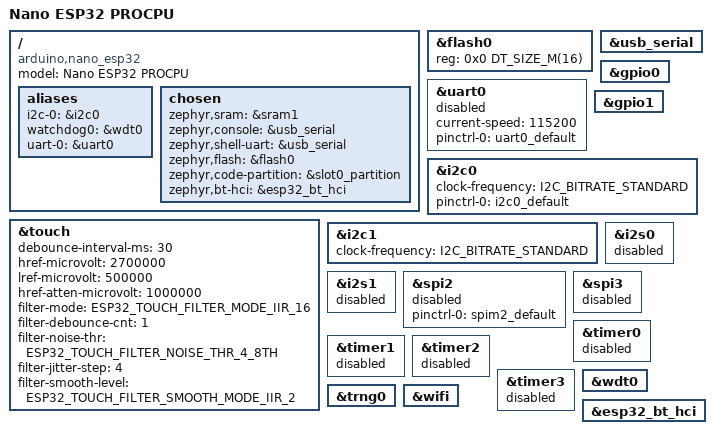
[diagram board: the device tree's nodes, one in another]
/*
 * Copyright (c) 2025 Arduino SA
 *
 * SPDX-License-Identifier: Apache-2.0
 */
/dts-v1/;

#include <espressif/esp32s3/esp32s3_r8.dtsi>
#include <zephyr/dt-bindings/input/input-event-codes.h>
#include <zephyr/dt-bindings/input/esp32-touch-sensor-input.h>
#include "arduino_nano_esp32-partitions.dtsi"
#include "arduino_nano_esp32-pinctrl.dtsi"
#include "arduino_nano_connector.dtsi"

/ {
	model = "Nano ESP32 PROCPU";
	compatible = "arduino,nano_esp32";

	aliases {
		i2c-0 = &i2c0;
		watchdog0 = &wdt0;
	};

	chosen {
		zephyr,sram = &sram1;
		zephyr,console = &usb_serial;
		zephyr,shell-uart = &usb_serial;
		zephyr,flash = &flash0;
		zephyr,code-partition = &slot0_partition;
		zephyr,bt-hci = &esp32_bt_hci;
	};

	aliases {
		uart-0 = &uart0;
	};
};

/* 16MB flash */
&flash0 {
	reg = <0x0 DT_SIZE_M(16)>;
};

&usb_serial {
	status = "okay";
};

&uart0 {
	current-speed = <115200>;
	pinctrl-0 = <&uart0_default>;
	pinctrl-names = "default";
	status = "disabled";
};

&gpio0 {
	status = "okay";
};

&gpio1 {
	status = "okay";
};

&touch {
	debounce-interval-ms = <30>;
	href-microvolt = <2700000>;
	lref-microvolt = <500000>;
	href-atten-microvolt = <1000000>;
	filter-mode = <ESP32_TOUCH_FILTER_MODE_IIR_16>;
	filter-debounce-cnt = <1>;
	filter-noise-thr = <ESP32_TOUCH_FILTER_NOISE_THR_4_8TH>;
	filter-jitter-step = <4>;
	filter-smooth-level = <ESP32_TOUCH_FILTER_SMOOTH_MODE_IIR_2>;
};

&i2c0 {
	clock-frequency = <I2C_BITRATE_STANDARD>;
	pinctrl-0 = <&i2c0_default>;
	pinctrl-names = "default";
};

&i2c1 {
	clock-frequency = <I2C_BITRATE_STANDARD>;
};

&i2s0 {
	status = "disabled";
};

&i2s1 {
	status = "disabled";
};

&spi2 {
	#address-cells = <1>;
	#size-cells = <0>;
	status = "disabled";
	pinctrl-0 = <&spim2_default>;
	pinctrl-names = "default";
};

&spi3 {
	#address-cells = <1>;
	#size-cells = <0>;
	status = "disabled";
};

&timer0 {
	status = "disabled";
};

&timer1 {
	status = "disabled";
};

&timer2 {
	status = "disabled";
};

&timer3 {
	status = "disabled";
};

&wdt0 {
	status = "okay";
};

&trng0 {
	status = "okay";
};

&esp32_bt_hci {
	status = "okay";
};

&wifi {
	status = "okay";
};
